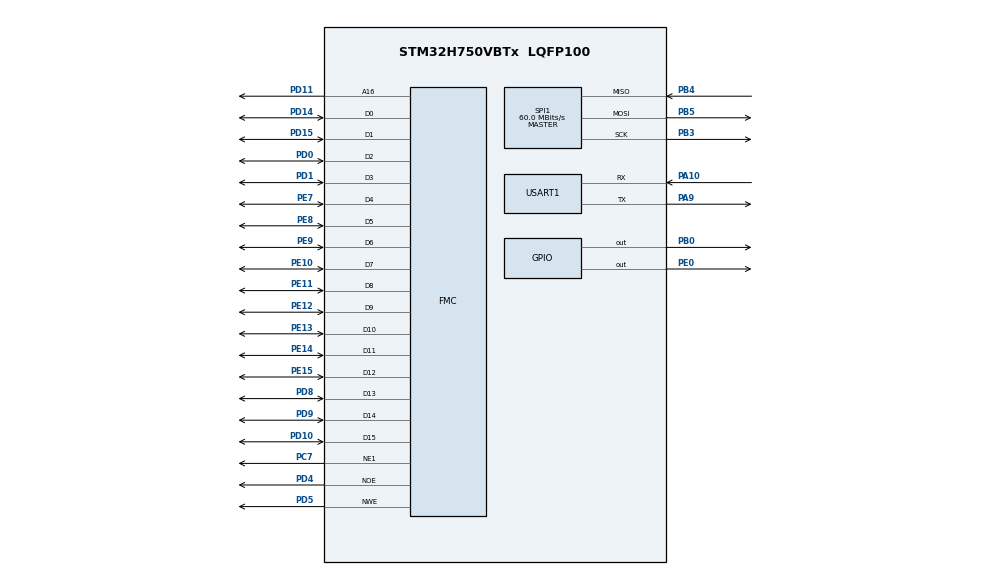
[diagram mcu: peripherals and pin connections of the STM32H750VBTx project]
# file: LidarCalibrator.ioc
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CORTEX_M7.AccessPermission_S-Cortex_Memory_Protection_Unit_Region1_Settings_S=MPU_REGION_FULL_ACCESS
CORTEX_M7.BaseAddress_S-Cortex_Memory_Protection_Unit_Region1_Settings_S=0x60000000
CORTEX_M7.CPU_DCache=Enabled
CORTEX_M7.CPU_ICache=Enabled
CORTEX_M7.Enable_S-Cortex_Memory_Protection_Unit_Region1_Settings_S=MPU_REGION_ENABLE
CORTEX_M7.IsShareable_S-Cortex_Memory_Protection_Unit_Region1_Settings_S=MPU_ACCESS_SHAREABLE
CORTEX_M7.Size_S-Cortex_Memory_Protection_Unit_Region1_Settings_S=MPU_REGION_SIZE_256MB
CORTEX_M7.default_mode_Activation=1
FMC.AddressSetupTime1=2
FMC.BusTurnAroundDuration1=0
FMC.DataSetupTime1=3
Mcu.Family=STM32H7
Mcu.Name=STM32H750VBTx
Mcu.Package=LQFP100
NVIC.PriorityGroup=NVIC_PRIORITYGROUP_4
NVIC.USART1_IRQn=true\:7\:0\:true\:false\:true\:true\:true\:true
PA10.GPIO_Speed=GPIO_SPEED_FREQ_HIGH
PA10.Mode=Asynchronous
PA10.Signal=USART1_RX
PA9.GPIO_Speed=GPIO_SPEED_FREQ_HIGH
PA9.Mode=Asynchronous
PA9.Signal=USART1_TX
PB0.GPIO_Speed=GPIO_SPEED_FREQ_VERY_HIGH
PB0.Signal=GPIO_Output
PB3\ (JTDO/TRACESWO).Mode=Full_Duplex_Master
PB3\ (JTDO/TRACESWO).Signal=SPI1_SCK
PB4\ (NJTRST).Mode=Full_Duplex_Master
PB4\ (NJTRST).Signal=SPI1_MISO
PB5.Mode=Full_Duplex_Master
PB5.Signal=SPI1_MOSI
PC7.Mode=NorPsramChipSelect1_1
PC7.Signal=FMC_NE1
PD0.Signal=FMC_D2_DA2
PD1.Signal=FMC_D3_DA3
PD10.Signal=FMC_D15_DA15
PD11.Signal=FMC_A16_CLE
PD14.Signal=FMC_D0_DA0
PD15.Signal=FMC_D1_DA1
PD4.Signal=FMC_NOE
PD5.Signal=FMC_NWE
PD8.Signal=FMC_D13_DA13
PD9.Signal=FMC_D14_DA14
PE0.Signal=GPIO_Output
PE10.Signal=FMC_D7_DA7
PE11.Signal=FMC_D8_DA8
PE12.Signal=FMC_D9_DA9
PE13.Signal=FMC_D10_DA10
PE14.Signal=FMC_D11_DA11
PE15.Signal=FMC_D12_DA12
PE7.Signal=FMC_D4_DA4
PE8.Signal=FMC_D5_DA5
PE9.Signal=FMC_D6_DA6
PH0-OSC_IN\ (PH0).Mode=HSE-External-Oscillator
PH0-OSC_IN\ (PH0).Signal=RCC_OSC_IN
PH1-OSC_OUT\ (PH1).Mode=HSE-External-Oscillator
PH1-OSC_OUT\ (PH1).Signal=RCC_OSC_OUT
ProjectManager.HeapSize=0x200
ProjectManager.StackSize=0x400
ProjectManager.TargetToolchain=MDK-ARM V5.32
RCC.ADCFreq_Value=120000000
RCC.APB1Freq_Value=120000000
RCC.APB2Freq_Value=120000000
RCC.APB3Freq_Value=120000000
RCC.APB4Freq_Value=120000000
RCC.CKPERSourceSelection=RCC_CLKPSOURCE_HSE
RCC.CortexFreq_Value=480000000
RCC.D1PPRE=RCC_APB3_DIV2
RCC.D2PPRE1=RCC_APB1_DIV2
RCC.D2PPRE2=RCC_APB2_DIV2
RCC.D3PPRE=RCC_APB4_DIV2
RCC.DIVM1=5
RCC.DIVM2=5
RCC.DIVM3=5
RCC.DIVN1=192
RCC.DIVN2=192
RCC.DIVN3=192
RCC.DIVP2=8
RCC.HCLKFreq_Value=240000000
RCC.HPRE=RCC_HCLK_DIV2
RCC.PLLSourceVirtual=RCC_PLLSOURCE_HSE
RCC.SPI123CLockSelection=RCC_SPI123CLKSOURCE_PLL2
RCC.SYSCLKFreq_VALUE=480000000
RCC.SYSCLKSource=RCC_SYSCLKSOURCE_PLLCLK
RCC.USBFreq_Value=480000000
SH.FMC_A16_CLE.0=FMC_A16,A16_1
SH.FMC_D0_DA0.0=FMC_D0,16b-d1
SH.FMC_D10_DA10.0=FMC_D10,16b-d1
SH.FMC_D11_DA11.0=FMC_D11,16b-d1
SH.FMC_D12_DA12.0=FMC_D12,16b-d1
SH.FMC_D13_DA13.0=FMC_D13,16b-d1
SH.FMC_D14_DA14.0=FMC_D14,16b-d1
SH.FMC_D15_DA15.0=FMC_D15,16b-d1
SH.FMC_D1_DA1.0=FMC_D1,16b-d1
SH.FMC_D2_DA2.0=FMC_D2,16b-d1
SH.FMC_D3_DA3.0=FMC_D3,16b-d1
SH.FMC_D4_DA4.0=FMC_D4,16b-d1
SH.FMC_D5_DA5.0=FMC_D5,16b-d1
SH.FMC_D6_DA6.0=FMC_D6,16b-d1
SH.FMC_D7_DA7.0=FMC_D7,16b-d1
SH.FMC_D8_DA8.0=FMC_D8,16b-d1
SH.FMC_D9_DA9.0=FMC_D9,16b-d1
SH.FMC_NOE.0=FMC_NOE,Lcd1
SH.FMC_NWE.0=FMC_NWE,Lcd1
SPI1.CLKPhase=SPI_PHASE_2EDGE
SPI1.CLKPolarity=SPI_POLARITY_HIGH
SPI1.CalculateBaudRate=60.0 MBits/s
SPI1.Direction=SPI_DIRECTION_2LINES
SPI1.Mode=SPI_MODE_MASTER
SPI1.VirtualType=VM_MASTER
USART1.VirtualMode-Asynchronous=VM_ASYNC
VP_MEMORYMAP_VS_MEMORYMAP.Mode=CurAppReg
board=custom

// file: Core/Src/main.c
/* USER CODE BEGIN Header */
/**
  ******************************************************************************
  * @file           : main.c
  * @brief          : Main program body
  ******************************************************************************
  * @attention
  *
  * Copyright (c) 2025 STMicroelectronics.
  * All rights reserved.
  *
  * This software is licensed under terms that can be found in the LICENSE file
  * in the root directory of this software component.
  * If no LICENSE file comes with this software, it is provided AS-IS.
  *
  ******************************************************************************
  */
/* USER CODE END Header */
#include "main.h"
#include "memorymap.h"
#include "spi.h"
#include "usart.h"
#include "gpio.h"
#include "fmc.h"

/* USER CODE BEGIN Includes */
#include "stdio.h"
#include "dac.h"
/* USER CODE END Includes */

void SystemClock_Config(void);
static void MPU_Config(void);

int main(void)
{

  /* MPU Configuration--------------------------------------------------------*/
  MPU_Config();

  /* Enable the CPU Cache */

  /* Enable I-Cache---------------------------------------------------------*/
  SCB_EnableICache();

  /* Enable D-Cache---------------------------------------------------------*/
  SCB_EnableDCache();

  /* MCU Configuration--------------------------------------------------------*/

  /* Reset of all peripherals, Initializes the Flash interface and the Systick. */
  HAL_Init();

  /* Configure the system clock */
  SystemClock_Config();

  /* Initialize all configured peripherals */
  MX_GPIO_Init();
  MX_USART1_UART_Init();
  MX_FMC_Init();
  MX_SPI1_Init();
  /* USER CODE BEGIN 2 */
  printf("Application Start\r\n");
  HAL_GPIO_WritePin(GPIOE, GPIO_PIN_0, GPIO_PIN_RESET);
  /* USER CODE END 2 */

  /* Infinite loop */
  while (1)
  {

    /* USER CODE BEGIN 3 */
    DAC_OutputWave();
    usart1_process();
  }
  /* USER CODE END 3 */
}

void SystemClock_Config(void)
{
  RCC_OscInitTypeDef RCC_OscInitStruct = {0};
  RCC_ClkInitTypeDef RCC_ClkInitStruct = {0};

  /** Supply configuration update enable
  */
  HAL_PWREx_ConfigSupply(PWR_LDO_SUPPLY);

  /** Configure the main internal regulator output voltage
  */
  __HAL_PWR_VOLTAGESCALING_CONFIG(PWR_REGULATOR_VOLTAGE_SCALE0);

  while(!__HAL_PWR_GET_FLAG(PWR_FLAG_VOSRDY)) {}

  /** Initializes the RCC Oscillators according to the specified parameters
  * in the RCC_OscInitTypeDef structure.
  */
  RCC_OscInitStruct.OscillatorType = RCC_OSCILLATORTYPE_HSE;
  RCC_OscInitStruct.HSEState = RCC_HSE_ON;
  RCC_OscInitStruct.PLL.PLLState = RCC_PLL_ON;
  RCC_OscInitStruct.PLL.PLLSource = RCC_PLLSOURCE_HSE;
  RCC_OscInitStruct.PLL.PLLM = 5;
  RCC_OscInitStruct.PLL.PLLN = 192;
  RCC_OscInitStruct.PLL.PLLP = 2;
  RCC_OscInitStruct.PLL.PLLQ = 2;
  RCC_OscInitStruct.PLL.PLLR = 2;
  RCC_OscInitStruct.PLL.PLLRGE = RCC_PLL1VCIRANGE_2;
  RCC_OscInitStruct.PLL.PLLVCOSEL = RCC_PLL1VCOWIDE;
  RCC_OscInitStruct.PLL.PLLFRACN = 0;
  if (HAL_RCC_OscConfig(&RCC_OscInitStruct) != HAL_OK)
  {
    Error_Handler();
  }

  /** Initializes the CPU, AHB and APB buses clocks
  */
  RCC_ClkInitStruct.ClockType = RCC_CLOCKTYPE_HCLK|RCC_CLOCKTYPE_SYSCLK
                              |RCC_CLOCKTYPE_PCLK1|RCC_CLOCKTYPE_PCLK2
                              |RCC_CLOCKTYPE_D3PCLK1|RCC_CLOCKTYPE_D1PCLK1;
  RCC_ClkInitStruct.SYSCLKSource = RCC_SYSCLKSOURCE_PLLCLK;
  RCC_ClkInitStruct.SYSCLKDivider = RCC_SYSCLK_DIV1;
  RCC_ClkInitStruct.AHBCLKDivider = RCC_HCLK_DIV2;
  RCC_ClkInitStruct.APB3CLKDivider = RCC_APB3_DIV2;
  RCC_ClkInitStruct.APB1CLKDivider = RCC_APB1_DIV2;
  RCC_ClkInitStruct.APB2CLKDivider = RCC_APB2_DIV2;
  RCC_ClkInitStruct.APB4CLKDivider = RCC_APB4_DIV2;

  if (HAL_RCC_ClockConfig(&RCC_ClkInitStruct, FLASH_LATENCY_4) != HAL_OK)
  {
    Error_Handler();
  }
}

 /* MPU Configuration */

void MPU_Config(void)
{
  MPU_Region_InitTypeDef MPU_InitStruct = {0};

  /* Disables the MPU */
  HAL_MPU_Disable();

  /** Initializes and configures the Region and the memory to be protected
  */
  MPU_InitStruct.Enable = MPU_REGION_ENABLE;
  MPU_InitStruct.Number = MPU_REGION_NUMBER0;
  MPU_InitStruct.BaseAddress = 0x0;
  MPU_InitStruct.Size = MPU_REGION_SIZE_4GB;
  MPU_InitStruct.SubRegionDisable = 0x87;
  MPU_InitStruct.TypeExtField = MPU_TEX_LEVEL0;
  MPU_InitStruct.AccessPermission = MPU_REGION_NO_ACCESS;
  MPU_InitStruct.DisableExec = MPU_INSTRUCTION_ACCESS_DISABLE;
  MPU_InitStruct.IsShareable = MPU_ACCESS_SHAREABLE;
  MPU_InitStruct.IsCacheable = MPU_ACCESS_NOT_CACHEABLE;
  MPU_InitStruct.IsBufferable = MPU_ACCESS_NOT_BUFFERABLE;

  HAL_MPU_ConfigRegion(&MPU_InitStruct);

  /** Initializes and configures the Region and the memory to be protected
  */
  MPU_InitStruct.Number = MPU_REGION_NUMBER1;
  MPU_InitStruct.BaseAddress = 0x60000000;
  MPU_InitStruct.Size = MPU_REGION_SIZE_256MB;
  MPU_InitStruct.SubRegionDisable = 0x0;
  MPU_InitStruct.AccessPermission = MPU_REGION_FULL_ACCESS;
  MPU_InitStruct.DisableExec = MPU_INSTRUCTION_ACCESS_ENABLE;

  HAL_MPU_ConfigRegion(&MPU_InitStruct);
  /* Enables the MPU */
  HAL_MPU_Enable(MPU_PRIVILEGED_DEFAULT);

}

void Error_Handler(void)
{
  __disable_irq();
  while (1)
  {
  }
}
